# STM32C092xx register map
File version: 1.0
Registers are 32-bit, read-write, reset 0x0 unless marked. A register's access mark holds for its fields unless they carry their own. Offsets are from the block's base; lines under a group give offsets from that group; [hi:lo] are bit positions; {n}, {i} and the like mark numbered series; 'fields as' and 'values as' point back to an identical list; <NAME> marks a mode.

## Memory map
0x40000000 TIM2 — TIM
0x40000400 TIM3 — TIM
0x40002000 TIM14 — TIM
0x40002800 RTC — Real-Time Clock
0x40002C00 WWDG — Window WATCHDOG
0x40003000 IWDG — Independent WATCHDOG
0x40003800 SPI2 — Serial Peripheral Interface
0x40004400 USART2 — Universal Synchronous Asynchronous Receiver Transmitter
0x40004800 USART3 — Universal Synchronous Asynchronous Receiver Transmitter
0x40004C00 USART4 — Universal Synchronous Asynchronous Receiver Transmitter
0x40005400 I2C1 — Inter-integrated Circuit Interface
0x40005800 I2C2 — Inter-integrated Circuit Interface
0x40006400 FDCAN1 — FD Controller Area Network
0x40006500 FDCAN_CONFIG — FD Controller Area Network Configuration
0x40007000 PWR — Power Control
0x40010000 SYSCFG — System configuration controller
0x40012400 ADC1 — Analog to Digital Converter
0x40012C00 TIM1 — TIM
0x40013000 SPI1 — Serial Peripheral Interface
0x40013800 USART1 — Universal Synchronous Asynchronous Receiver Transmitter
0x40014000 TIM15 — TIM
0x40014400 TIM16 — TIM
0x40014800 TIM17 — TIM
0x40015800 DBG — Debug MCU
0x40020000 DMA1
0x40020800 DMAMUX1 — DMA Multiplexer
0x40021000 RCC — Reset and Clock Control
0x40021800 EXTI — Asynch Interrupt/Event Controller (EXTI)
0x40022000 FLASH — FLASH Registers
0x40023000 CRC — CRC calculation unit
0x50000000 GPIOA — General Purpose I/O
0x50000400 GPIOB — General Purpose I/O
0x50000800 GPIOC — General Purpose I/O
0x50000C00 GPIOD — General Purpose I/O
0x50001400 GPIOF — General Purpose I/O

## Interrupts
0 WWDG — Window WatchDog Interrupt
2 RTC — RTC interrupt through the EXTI line 19 & 21
3 FLASH — FLASH global Interrupt
4 RCC — RCC global Interrupt
5 EXTI0_1 (EXTI) — EXTI 0 and 1 Interrupts
6 EXTI2_3 (EXTI) — EXTI Line 2 and 3 Interrupts
7 EXTI4_15 (EXTI) — EXTI Line 4 to 15 Interrupts
9 DMA1_Channel1 (DMA1) — DMA1 Channel 1 Interrupt
10 DMA1_Channel2_3 (DMA1) — DMA1 Channel 2 and Channel 3 Interrupts
11 DMAMUX1_DMA1_CH4_5_6_7 (DMA1, DMAMUX1) — DMAMUX and DMA1 Channel 4 to Channel 7 Interrupts
12 ADC1 — ADC1 Interrupts
13 TIM1_BRK_UP_TRG_COM (TIM1) — TIM1 Break, Update, Trigger and Commutation Interrupts
14 TIM1_CC (TIM1) — TIM1 Capture Compare Interrupt
15 TIM2 — TIM2 global Interrupt
16 TIM3 — TIM3 global Interrupt
19 TIM14 — TIM14 global Interrupt
20 TIM15 — TIM15 global Interrupt
21 TIM16 — TIM16 global Interrupt
22 TIM17 — TIM17 global Interrupt
23 I2C1 — I2C1 Interrupt (combined with EXTI 23)
24 I2C2 — I2C2 Interrupt
25 SPI1 — SPI1 Interrupt
26 SPI2 — SPI2 Interrupt
27 USART1 — USART1 Interrupt
28 USART2 — USART2 Interrupt
29 USART3_4 (USART3) — USART3/4 global interrupt(combined with EXTI 28)
30 FDCAN1_IT0 (FDCAN1) — FDCAN1 global Interrupt 0
31 FDCAN1_IT1 (FDCAN1) — FDCAN1 global Interrupt 1

## RTC — Real-Time Clock
Base 0x40002800
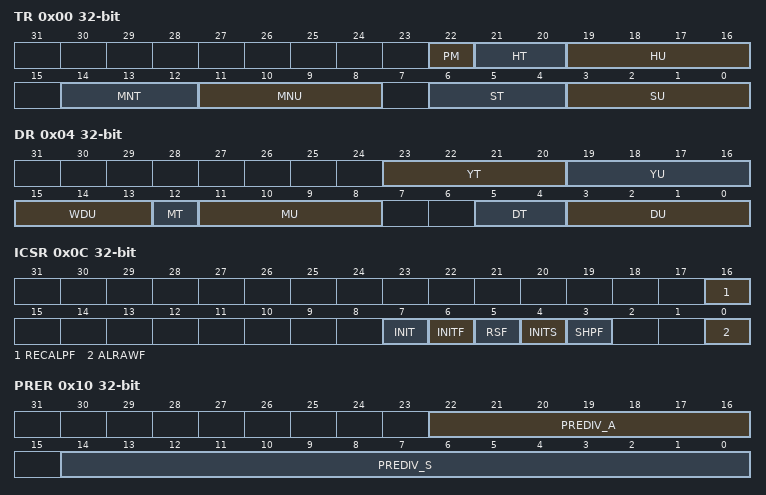
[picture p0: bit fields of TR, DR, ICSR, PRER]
0x00 TR — RTC time register
  [22] PM
    0=AM_OR_24 (AM or 24-hour format); 1=PM
  [21:20] HT
  [19:16] HU
  [14:12] MNT
  [11:8] MNU
  [6:4] ST
  [3:0] SU
0x04 DR — RTC date register
  [23:20] YT, [19:16] YU, [15:13] WDU, [12] MT, [11:8] MU, [5:4] DT, [3:0] DU
0x08 SSR — RTC sub second register
  [15:0] SS
0x0C ICSR — RTC initialization control and status register
  [16] RECALPF, [7] INIT, [6] INITF, [5] RSF, [4] INITS, [3] SHPF, [0] ALRAWF
0x10 PRER — RTC prescaler register
  [22:16] PREDIV_A, [14:0] PREDIV_S
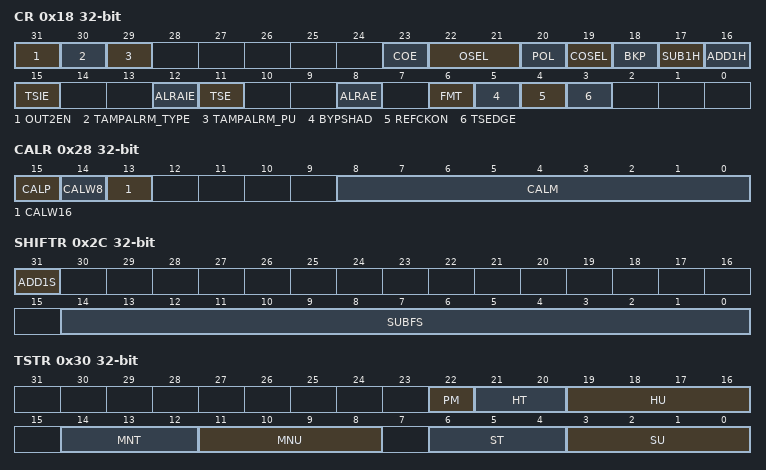
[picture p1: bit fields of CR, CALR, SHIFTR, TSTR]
0x18 CR — RTC control register
  [31] OUT2EN — RTC_OUT2 output enable
  [30] TAMPALRM_TYPE — TAMPALARM output type
    1=OPENDRAIN (RTC_ALARM is open-drain output); 0=PUSHPULL (RTC_ALARM is push-pull output)
  [29] TAMPALRM_PU — TAMPALARM output pull-up config
  [23] COE
  [22:21] OSEL
    0=DISABLE (Output disabled); 1=ALMA (Alarm A output enabled)
  [20] POL
    0=HIGH (Pin is high when ALRAF is asserted (depending on OSEL)); 1=LOW (Pin is low when ALRAF is asserted (depending on OSEL))
  [19] COSEL
  [18] BKP
  [17] SUB1H
  [16] ADD1H
  [15] TSIE — Timestamp interrupt enable >
  [12] ALRAIE
  [11] TSE — timestamp enable >
  [8] ALRAE
  [6] FMT
    0=HOURFORMAT_24HOUR (24 hour/day format); 1=AMPM (AM/PM hour format)
  [5] BYPSHAD
  [4] REFCKON
  [3] TSEDGE — Timestamp event active edge >
    0=RISING (RTC_TS input rising edge generates a time-stamp event); 1=FALLING (RTC_TS input falling edge generates a time-stamp even)
0x24 WPR — RTC write protection register
  [7:0] KEY
0x28 CALR — RTC calibration register
  [15] CALP
    0=NONE (No RTCCLK pulses are added); 1=SET (One RTCCLK pulse is effectively inserted every 2exp11 pulses (frequency increased by 488.5 ppm))
  [14] CALW8
  [13] CALW16
  [8:0] CALM
0x2C SHIFTR — RTC shift control register
  [31] ADD1S, [14:0] SUBFS
0x30 TSTR — RTC time stamp time register
  [22] PM — AM-PM notation >
    0=AM (AM or 24-hour format); 1=PM
  [21:20] HT
  [19:16] HU
  [14:12] MNT
  [11:8] MNU
  [6:4] ST
  [3:0] SU
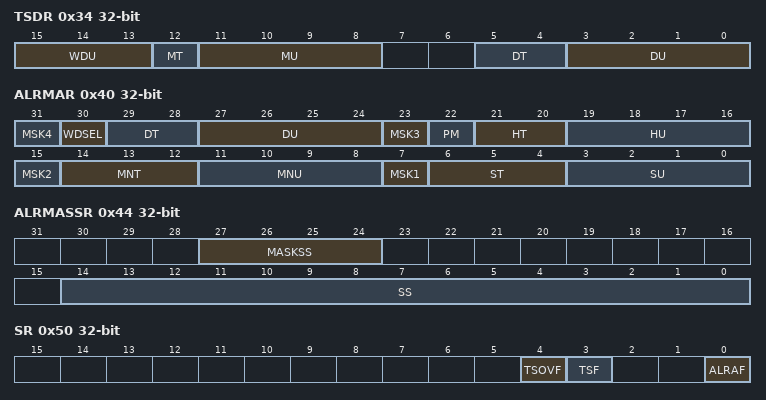
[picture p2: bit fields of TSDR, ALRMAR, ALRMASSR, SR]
0x34 TSDR — RTC time stamp date register
  [15:13] WDU — Week day units >
  [12] MT
  [11:8] MU
  [5:4] DT
  [3:0] DU
0x38 TSSSR — RTC time-stamp sub second register
  [15:0] SS — Sub second value >
0x40 ALRMAR — RTC alarm A register
  [8n-1] MSK{n} (n=1..4)
  [30] WDSEL
  [29:28] DT
  [27:24] DU
  [22] PM
    0=AM (AM or 24-hour format); 1=PM
  [21:20] HT
  [19:16] HU
  [14:12] MNT
  [11:8] MNU
  [6:4] ST
  [3:0] SU
0x44 ALRMASSR — RTC alarm A sub second register
  [27:24] MASKSS, [14:0] SS
0x50 SR — RTC Status register
  [4] TSOVF — Timestamp overflow flag >
  [3] TSF — Timestamp flag >
  [0] ALRAF
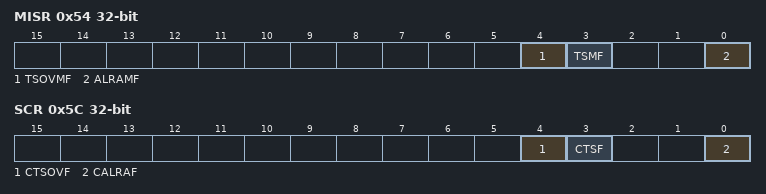
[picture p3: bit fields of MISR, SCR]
0x54 MISR — RTC Masked Interrupt Status register
  [4] TSOVMF — Timestamp overflow masked flag >
  [3] TSMF — Timestamp masked flag >
  [0] ALRAMF
0x5C SCR — RTC Status Clear register
  [4] CTSOVF — Clear timestamp overflow flag >
  [3] CTSF — Clear timestamp flag >
  [0] CALRAF
